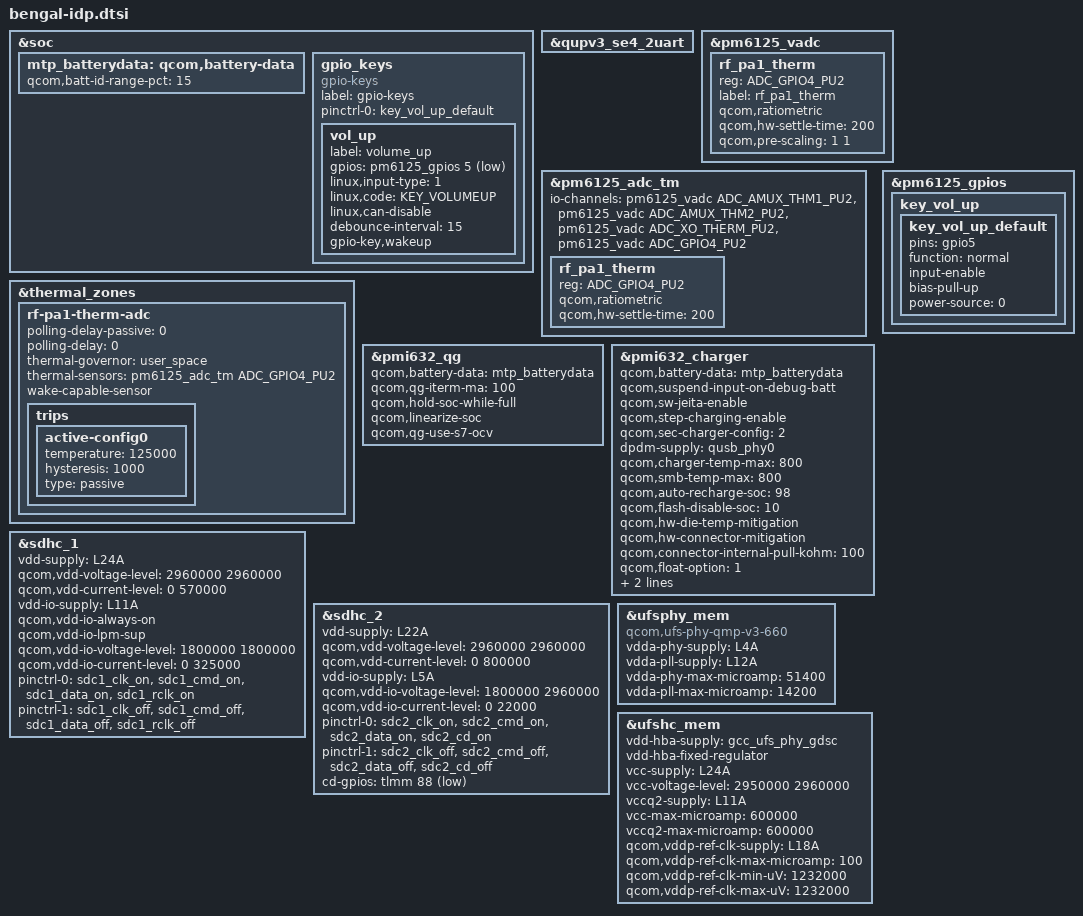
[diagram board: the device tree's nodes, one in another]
#include <dt-bindings/gpio/gpio.h>
#include <dt-bindings/iio/qcom,spmi-vadc.h>
#include <dt-bindings/input/input.h>
#include "bengal-audio-overlay.dtsi"
#include "bengal-thermal-overlay.dtsi"

&soc {
	mtp_batterydata: qcom,battery-data {
		qcom,batt-id-range-pct = <15>;
		#include "qg-batterydata-alium-3600mah.dtsi"
	};
};

&qupv3_se4_2uart {
	status = "ok";
};

&pm6125_vadc {
	rf_pa1_therm {
		reg = <ADC_GPIO4_PU2>;
		label = "rf_pa1_therm";
		qcom,ratiometric;
		qcom,hw-settle-time = <200>;
		qcom,pre-scaling = <1 1>;
	};
};

&pm6125_adc_tm {
	io-channels = <&pm6125_vadc ADC_AMUX_THM1_PU2>,
			<&pm6125_vadc ADC_AMUX_THM2_PU2>,
			<&pm6125_vadc ADC_XO_THERM_PU2>,
			<&pm6125_vadc ADC_GPIO4_PU2>;

	rf_pa1_therm {
		reg = <ADC_GPIO4_PU2>;
		qcom,ratiometric;
		qcom,hw-settle-time = <200>;
	};
};

&thermal_zones {
	rf-pa1-therm-adc {
		polling-delay-passive = <0>;
		polling-delay = <0>;
		thermal-governor = "user_space";
		thermal-sensors = <&pm6125_adc_tm ADC_GPIO4_PU2>;
		wake-capable-sensor;
		trips {
			active-config0 {
				temperature = <125000>;
				hysteresis = <1000>;
				type = "passive";
			};
		};
	};
};

&pmi632_qg {
	qcom,battery-data = <&mtp_batterydata>;
	qcom,qg-iterm-ma = <100>;
	qcom,hold-soc-while-full;
	qcom,linearize-soc;
	qcom,qg-use-s7-ocv;
};

&pmi632_charger {
	qcom,battery-data = <&mtp_batterydata>;
	qcom,suspend-input-on-debug-batt;
	qcom,sw-jeita-enable;
	qcom,step-charging-enable;
	/* SMB1355 only */
	qcom,sec-charger-config = <2>;
	dpdm-supply = <&qusb_phy0>;
	qcom,charger-temp-max = <800>;
	qcom,smb-temp-max = <800>;
	qcom,auto-recharge-soc = <98>;
	qcom,flash-disable-soc = <10>;
	qcom,hw-die-temp-mitigation;
	qcom,hw-connector-mitigation;
	qcom,connector-internal-pull-kohm = <100>;
	qcom,float-option = <1>;
	qcom,thermal-mitigation = <3000000 2500000
			2000000 1500000 1000000 500000>;
};

&pm6125_gpios {
	key_vol_up {
		key_vol_up_default: key_vol_up_default {
			pins = "gpio5";
			function = "normal";
			input-enable;
			bias-pull-up;
			power-source = <0>;
		};
	};
};

&soc {
	gpio_keys {
		compatible = "gpio-keys";
		label = "gpio-keys";

		pinctrl-names = "default";
		pinctrl-0 = <&key_vol_up_default>;

		vol_up {
			label = "volume_up";
			gpios = <&pm6125_gpios 5 GPIO_ACTIVE_LOW>;
			linux,input-type = <1>;
			linux,code = <KEY_VOLUMEUP>;
			linux,can-disable;
			debounce-interval = <15>;
			gpio-key,wakeup;
		};
	};
};

&sdhc_1 {
	vdd-supply = <&L24A>;
	qcom,vdd-voltage-level = <2960000 2960000>;
	qcom,vdd-current-level = <0 570000>;

	vdd-io-supply = <&L11A>;
	qcom,vdd-io-always-on;
	qcom,vdd-io-lpm-sup;
	qcom,vdd-io-voltage-level = <1800000 1800000>;
	qcom,vdd-io-current-level = <0 325000>;

	pinctrl-names = "active", "sleep";
	pinctrl-0 = <&sdc1_clk_on &sdc1_cmd_on &sdc1_data_on
					&sdc1_rclk_on>;
	pinctrl-1 = <&sdc1_clk_off &sdc1_cmd_off &sdc1_data_off
					&sdc1_rclk_off>;

	status = "ok";
};

&sdhc_2 {
	vdd-supply = <&L22A>;
	qcom,vdd-voltage-level = <2960000 2960000>;
	qcom,vdd-current-level = <0 800000>;

	vdd-io-supply = <&L5A>;
	qcom,vdd-io-voltage-level = <1800000 2960000>;
	qcom,vdd-io-current-level = <0 22000>;

	pinctrl-names = "active", "sleep";
	pinctrl-0 = <&sdc2_clk_on  &sdc2_cmd_on &sdc2_data_on &sdc2_cd_on>;
	pinctrl-1 = <&sdc2_clk_off &sdc2_cmd_off &sdc2_data_off &sdc2_cd_off>;

	cd-gpios = <&tlmm 88 GPIO_ACTIVE_LOW>;

	status = "ok";
};

&ufsphy_mem {
	compatible = "qcom,ufs-phy-qmp-v3-660";

	vdda-phy-supply = <&L4A>; /* 0.9v */
	vdda-pll-supply = <&L12A>; /* 1.8v */
	vdda-phy-max-microamp = <51400>;
	vdda-pll-max-microamp = <14200>;

	status = "ok";
};

&ufshc_mem {
	vdd-hba-supply = <&gcc_ufs_phy_gdsc>;
	vdd-hba-fixed-regulator;
	vcc-supply = <&L24A>;
	vcc-voltage-level = <2950000 2960000>;
	vccq2-supply = <&L11A>;
	vcc-max-microamp = <600000>;
	vccq2-max-microamp = <600000>;

	qcom,vddp-ref-clk-supply = <&L18A>;
	qcom,vddp-ref-clk-max-microamp = <100>;
	qcom,vddp-ref-clk-min-uV = <1232000>;
	qcom,vddp-ref-clk-max-uV = <1232000>;

	status = "ok";
};
